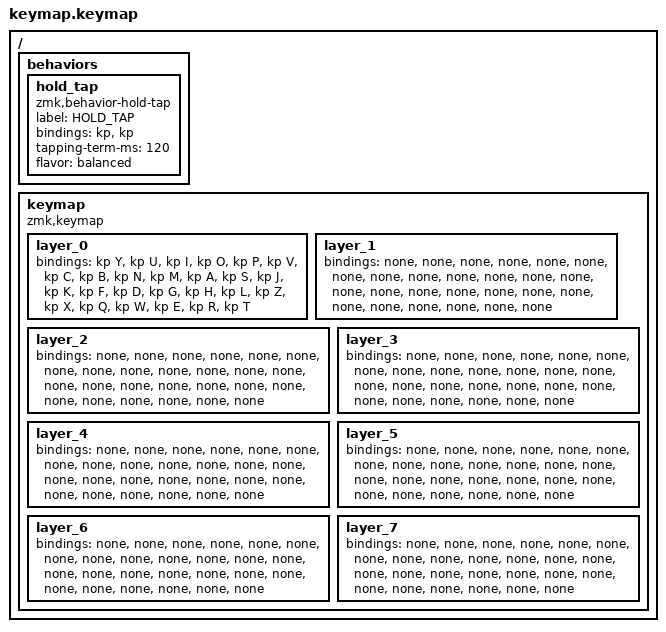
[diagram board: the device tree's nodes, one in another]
#define ZMK_POINTING_DEFAULT_SCRL_VAL 30

#include <behaviors.dtsi>
#include <dt-bindings/zmk/keys.h>

/ {
    behaviors {
        hold_tap: hold_tap {
            compatible = "zmk,behavior-hold-tap";
            label = "HOLD_TAP";
            bindings = <&kp>, <&kp>;

            #binding-cells = <2>;
            tapping-term-ms = <120>;
            flavor = "balanced";
        };
    };

    keymap {
        compatible = "zmk,keymap";

        layer_0 {
            bindings = <
&kp Y
&kp U
&kp I
&kp O
&kp P
&kp V
&kp C
&kp B
&kp N
&kp M
&kp A
&kp S
&kp J
&kp K
&kp F
&kp D
&kp G
&kp H
&kp L
&kp Z
&kp X
&kp Q
&kp W
&kp E
&kp R
&kp T
            >;
        };

        layer_1 {
            bindings = <
&none
&none
&none
&none
&none
&none
&none
&none
&none
&none
&none
&none
&none
&none
&none
&none
&none
&none
&none
&none
&none
&none
&none
&none
&none
&none
            >;
        };

        layer_2 {
            bindings = <
&none
&none
&none
&none
&none
&none
&none
&none
&none
&none
&none
&none
&none
&none
&none
&none
&none
&none
&none
&none
&none
&none
&none
&none
&none
&none
            >;
        };

        layer_3 {
            bindings = <
&none
&none
&none
&none
&none
&none
&none
&none
&none
&none
&none
&none
&none
&none
&none
&none
&none
&none
&none
&none
&none
&none
&none
&none
&none
&none
            >;
        };

        layer_4 {
            bindings = <
&none
&none
&none
&none
&none
&none
&none
&none
&none
&none
&none
&none
&none
&none
&none
&none
&none
&none
&none
&none
&none
&none
&none
&none
&none
&none
            >;
        };

        layer_5 {
            bindings = <
&none
&none
&none
&none
&none
&none
&none
&none
&none
&none
&none
&none
&none
&none
&none
&none
&none
&none
&none
&none
&none
&none
&none
&none
&none
&none
            >;
        };

        layer_6 {
            bindings = <
&none
&none
&none
&none
&none
&none
&none
&none
&none
&none
&none
&none
&none
&none
&none
&none
&none
&none
&none
&none
&none
&none
&none
&none
&none
&none
            >;
        };

        layer_7 {
            bindings = <
&none
&none
&none
&none
&none
&none
&none
&none
&none
&none
&none
&none
&none
&none
&none
&none
&none
&none
&none
&none
&none
&none
&none
&none
&none
&none
            >;
        };
    };
};
